# ATmega3290PA register map
Vendor: Atmel; File version: 1.0
CPU: other r0p0, little endian, no MPU, no FPU, 4 interrupt priority bits
Registers are 8-bit, read-write, reset 0x0 unless marked. A register's access mark holds for its fields unless they carry their own. Offsets are from the block's base; [hi:lo] are bit positions.

## LOCKBIT — Lockbits
Base 0x00000000
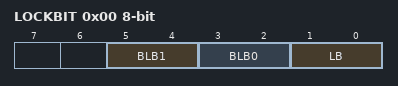
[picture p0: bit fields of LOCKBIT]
0x00 LOCKBIT
  [5:4] BLB1 — Boot Loader Protection Mode
    0=LPM_SPM_DISABLE (LPM and SPM prohibited in Boot Section); 1=LPM_DISABLE (LPM prohibited in Boot Section); 2=SPM_DISABLE (SPM prohibited in Boot Section); 3=NO_LOCK (No lock on SPM and LPM in Boot Section)
  [3:2] BLB0 — Boot Loader Protection Mode
    0=LPM_SPM_DISABLE (LPM and SPM prohibited in Application Section); 1=LPM_DISABLE (LPM prohibited in Application Section); 2=SPM_DISABLE (SPM prohibited in Application Section); 3=NO_LOCK (No lock on SPM and LPM in Application Section)
  [1:0] LB — Memory Lock
    0=PROG_VER_DISABLED (Further programming and verification disabled); 2=PROG_DISABLED (Further programming disabled); 3=NO_LOCK (No memory lock features enabled)

## PORTA — I/O Port
Base 0x00000020
0x00 PINA — Port A Input Pins
0x01 DDRA — Port A Data Direction Register
0x02 PORTA — Port A Data Register

## PORTB — I/O Port
Base 0x00000023
0x00 PINB — Port B Input Pins
0x01 DDRB — Port B Data Direction Register
0x02 PORTB — Port B Data Register

## PORTC — I/O Port
Base 0x00000026
0x00 PINC — Port C Input Pins
0x01 DDRC — Port C Data Direction Register
0x02 PORTC — Port C Data Register

## PORTD — I/O Port
Base 0x00000029
0x00 PIND — Port D Input Pins
0x01 DDRD — Port D Data Direction Register
0x02 PORTD — Port D Data Register

## PORTE — I/O Port
Base 0x0000002C
0x00 PINE — Input Pins, Port E
0x01 DDRE — Data Direction Register, Port E
0x02 PORTE — Data Register, Port E

## PORTF — I/O Port
Base 0x0000002F
0x00 PINF — Input Pins, Port F
0x01 DDRF — Data Direction Register, Port F
0x02 PORTF — Data Register, Port F

## PORTG — I/O Port
Base 0x00000032
0x00 PING — Port G Input Pins
0x01 DDRG — Port G Data Direction Register
0x02 PORTG — Port G Data Register

## PORTH — I/O Port
Base 0x000000D8
0x00 PINH — PORT H Input Pins
0x01 DDRH — PORT H Data Direction Register
0x02 PORTH — PORT H Data Register

## PORTJ — I/O Port
Base 0x000000DB
0x00 PINJ — PORT J Input Pins
0x01 DDRJ — PORT J Data Direction Register
0x02 PORTJ — PORT J Data Register

## SPI — Serial Peripheral Interface
Base 0x0000004C
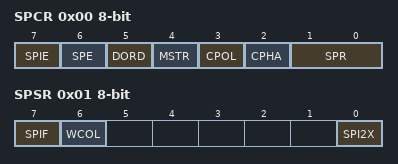
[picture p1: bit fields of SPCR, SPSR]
0x00 SPCR — SPI Control Register
  [7] SPIE — SPI Interrupt Enable
  [6] SPE — SPI Enable
  [5] DORD — Data Order
  [4] MSTR — Master/Slave Select
  [3] CPOL — Clock polarity
  [2] CPHA — Clock Phase
  [1:0] SPR — SPI Clock Rate Selects
    0=fosc/4; 1=fosc/16; 2=fosc/64; 3=fosc/128
0x01 SPSR — SPI Status Register
  [7] SPIF — SPI Interrupt Flag
  [6] WCOL — Write Collision Flag
  [0] SPI2X — Double SPI Speed Bit
0x02 SPDR — SPI Data Register

## TC0 — Timer/Counter, 8-bit
Base 0x00000035
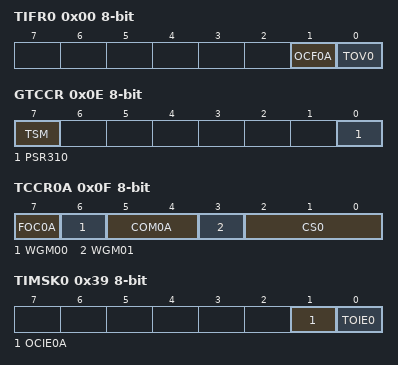
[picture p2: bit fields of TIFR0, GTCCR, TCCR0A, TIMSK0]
0x00 TIFR0 — Timer/Counter0 Interrupt Flag register
  [1] OCF0A — Timer/Counter0 Output Compare Flag 0
  [0] TOV0 — Timer/Counter0 Overflow Flag
0x0E GTCCR — General Timer/Control Register
  [7] TSM — Timer/Counter Synchronization Mode
  [0] PSR310 — Prescaler Reset Timer/Counter1 and Timer/Counter0
0x0F TCCR0A — Timer/Counter0 Control Register
  [7] FOC0A — Force Output Compare
  [6] WGM00 — Waveform Generation Mode 0
    0=Normal; 1=CTC
  [5:4] COM0A — Compare Match Output Modes
  [3] WGM01 — Waveform Generation Mode 1
  [2:0] CS0 — Clock Selects
    0=No Clock Source (Stopped); 1=Running, No Prescaling; 2=Running, CLK/8; 3=Running, CLK/64; 4=Running, CLK/256; 5=Running, CLK/1024; 6=Running, ExtClk Tx Falling Edge; 7=Running, ExtClk Tx Rising Edge
0x11 TCNT0 — Timer/Counter0
0x12 OCR0A — Timer/Counter0 Output Compare Register
0x39 TIMSK0 — Timer/Counter0 Interrupt Mask Register
  [1] OCIE0A — Timer/Counter0 Output Compare Match Interrupt Enable
  [0] TOIE0 — Timer/Counter0 Overflow Interrupt Enable
